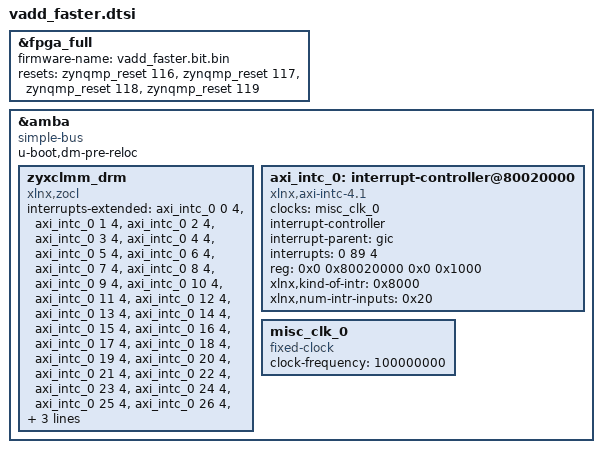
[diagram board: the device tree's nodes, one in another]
/dts-v1/;
/plugin/;

&fpga_full {
	#address-cells = <2>;
	#size-cells = <2>;
	firmware-name = "vadd_faster.bit.bin";
	resets = <&zynqmp_reset 116>, <&zynqmp_reset 117>, <&zynqmp_reset 118>, <&zynqmp_reset 119>;
};

&amba {
	compatible = "simple-bus";
	u-boot,dm-pre-reloc;
	#address-cells = <0x02>;
	#size-cells = <0x02>;

	zyxclmm_drm {
		// compatible = "xlnx,zocl";
		// status = "okay";
		compatible = "xlnx,zocl";
		interrupts-extended = <&axi_intc_0 0 4>, <&axi_intc_0 1 4>, <&axi_intc_0 2 4>, <&axi_intc_0 3 4>, <&axi_intc_0 4 4>, <&axi_intc_0 5 4>, 
			<&axi_intc_0 6 4>, <&axi_intc_0 7 4>, <&axi_intc_0 8 4>, <&axi_intc_0 9 4>,
			<&axi_intc_0 10 4>, <&axi_intc_0 11 4>, <&axi_intc_0 12 4>, <&axi_intc_0 13 4>, <&axi_intc_0 14 4>,
			<&axi_intc_0 15 4>, <&axi_intc_0 16 4>, <&axi_intc_0 17 4>, <&axi_intc_0 18 4>, <&axi_intc_0 19 4>,
			<&axi_intc_0 20 4>, <&axi_intc_0 21 4>, <&axi_intc_0 22 4>, <&axi_intc_0 23 4>, <&axi_intc_0 24 4>,
			<&axi_intc_0 25 4>, <&axi_intc_0 26 4>, <&axi_intc_0 27 4>, <&axi_intc_0 28 4>, <&axi_intc_0 29 4>,
			<&axi_intc_0 30 4>, <&axi_intc_0 31 4 >;
	};

	axi_intc_0: interrupt-controller@80020000 {
		#interrupt-cells = <2>;
		clock-names = "s_axi_aclk";
		clocks = <&misc_clk_0>;
		compatible = "xlnx,axi-intc-4.1", "xlnx,xps-intc-1.00.a";
		interrupt-controller ;
		interrupt-names = "irq";
		interrupt-parent = <&gic>;
		// interrupt-parent = <"/axi/interrupt-controller@f9010000">;
		interrupts = <0 89 4>;
		reg = <0x0 0x80020000 0x0 0x1000>;
		xlnx,kind-of-intr = <0x8000>;
		xlnx,num-intr-inputs = <0x20>;
	};

	misc_clk_0: misc_clk_0 {
		#clock-cells = <0>;
		clock-frequency = <100000000>;
		compatible = "fixed-clock";
	};
};


// / {
// 	compatible = "xlnx,zynqmp-sk-kv260-revB\0xlnx,zynqmp-sk-kv260-revA\0xlnx,zynqmp-sk-kv260-revY\0xlnx,zynqmp-sk-kv260-revZ\0xlnx,zynqmp-sk-kv260\0xlnx,zynqmp";

// 	amba_pl: amba_pl@0 {
// 		#address-cells = <2>;
// 		#size-cells = <2>;
// 		compatible = "simple-bus";
// 		ranges ;
// 		axi_intc_0: interrupt-controller@80020000 {
// 			#interrupt-cells = <2>;
// 			clock-names = "s_axi_aclk";
// 			clocks = <&misc_clk_0>;
// 			compatible = "xlnx,axi-intc-4.1", "xlnx,xps-intc-1.00.a";
// 			interrupt-controller ;
// 			interrupt-names = "irq";
// 			interrupt-parent = <&gic>;
// 			// interrupt-parent = <"/axi/interrupt-controller@f9010000">;
// 			interrupts = <0 89 4>;
// 			reg = <0x0 0x80020000 0x0 0x1000>;
// 			xlnx,kind-of-intr = <0x8000>;
// 			xlnx,num-intr-inputs = <0x20>;
// 		};
// 		misc_clk_0: misc_clk_0 {
// 			#clock-cells = <0>;
// 			clock-frequency = <100000000>;
// 			compatible = "fixed-clock";
// 		};
// 		axi_mcdma_0: axi_mcdma@80000000 {
// 			#dma-cells = <1>;
// 			clock-names = "s_axi_aclk", "s_axi_lite_aclk";
// 			clocks = <&misc_clk_1>, <&misc_clk_0>;
// 			compatible = "xlnx,axi-mcdma-1.1", "xlnx,axi-mcdma-1.00.a";
// 			interrupt-names = "mm2s_ch1_introut", "mm2s_ch2_introut", "s2mm_ch1_introut", "s2mm_ch2_introut", "s2mm_ch3_introut", "s2mm_ch4_introut";
// 			interrupt-parent = <&axi_intc_0>;
// 			interrupts = <9 2 10 2 11 2 12 2 13 2 14 2>;
// 			reg = <0x0 0x80000000 0x0 0x1000>;
// 			xlnx,addrwidth = <0x20>;
// 			xlnx,dlytmr-resolution = <0x7d>;
// 			xlnx,enable-single-intr = <0x0>;
// 			xlnx,group1-mm2s = <0xb>;
// 			xlnx,group1-s2mm = <0x457>;
// 			xlnx,group2-mm2s = <0x0>;
// 			xlnx,group2-s2mm = <0x0>;
// 			xlnx,group3-mm2s = <0x0>;
// 			xlnx,group3-s2mm = <0x0>;
// 			xlnx,group4-mm2s = <0x0>;
// 			xlnx,group4-s2mm = <0x0>;
// 			xlnx,group5-mm2s = <0x0>;
// 			xlnx,group5-s2mm = <0x0>;
// 			xlnx,group6-mm2s = <0x0>;
// 			xlnx,group6-s2mm = <0x0>;
// 			xlnx,include-dre ;
// 			xlnx,include-mm2s = <0x1>;
// 			xlnx,include-mm2s-dre = <0x1>;
// 			xlnx,include-mm2s-sf = <0x1>;
// 			xlnx,include-s2mm = <0x1>;
// 			xlnx,include-s2mm-dre = <0x1>;
// 			xlnx,include-s2mm-sf = <0x1>;
// 			xlnx,include-sg ;
// 			xlnx,mm2s-burst-size = <0x10>;
// 			xlnx,mm2s-scheduler = <0x0>;
// 			xlnx,num-mm2s-channels = <0x2>;
// 			xlnx,num-s2mm-channels = <0x4>;
// 			xlnx,prmry-is-aclk-async = <0x0>;
// 			xlnx,s2mm-burst-size = <0x10>;
// 			xlnx,sg-include-stscntrl-strm = <0x0>;
// 			xlnx,sg-length-width = <0xe>;
// 			xlnx,sg-use-stsapp-length = <0x0>;
// 			dma-channel@80000000 {
// 				compatible = "xlnx,axi-dma-mm2s-channel";
// 				dma-channels = <0x2>;
// 				interrupt-parent = <&axi_intc_0>;
// 				interrupts = <9 2 10 2>;
// 				xlnx,datawidth = <0x20>;
// 				xlnx,device-id = <0x0>;
// 				xlnx,include-dre ;
// 			};
// 			dma-channel@80000030 {
// 				compatible = "xlnx,axi-dma-s2mm-channel";
// 				dma-channels = <0x4>;
// 				interrupt-parent = <&axi_intc_0>;
// 				interrupts = <11 2 12 2 13 2 14 2>;
// 				xlnx,datawidth = <0x20>;
// 				xlnx,device-id = <0x0>;
// 				xlnx,include-dre ;
// 			};
// 		};
// 		misc_clk_1: misc_clk_1 {
// 			#clock-cells = <0>;
// 			clock-frequency = <200000000>;
// 			compatible = "fixed-clock";
// 		};
// 		axi_uartlite_0: serial@80010000 {
// 			clock-names = "s_axi_aclk";
// 			clocks = <&misc_clk_0>;
// 			compatible = "xlnx,axi-uartlite-2.0", "xlnx,xps-uartlite-1.00.a";
// 			current-speed = <9600>;
// 			device_type = "serial";
// 			interrupt-names = "interrupt";
// 			interrupt-parent = <&axi_intc_0>;
// 			interrupts = <15 0>;
// 			port-number = <1>;
// 			reg = <0x0 0x80010000 0x0 0x10000>;
// 			xlnx,baudrate = <0x2580>;
// 			xlnx,data-bits = <0x8>;
// 			xlnx,odd-parity = <0x0>;
// 			xlnx,s-axi-aclk-freq-hz-d = "100.0";
// 			xlnx,txen-delay = <0x0>;
// 			xlnx,use-parity = <0x0>;
// 		};
// 		// tsn_endpoint_ip_0: tsn_endpoint_ip_0 {
// 		// 	#address-cells = <2>;
// 		// 	#size-cells = <2>;
// 		// 	clock-names = "host_txfifo_aclk", "host_rxfifo_aclk", "s_axi_aclk", "gtx_clk", "gtx_clk90", "refclk";
// 		// 	clocks = <&misc_clk_1>, <&misc_clk_1>, <&misc_clk_0>, <&misc_clk_2>, <&misc_clk_2>, <&misc_clk_3>;
// 		// 	compatible = "xlnx,tsn-endpoint-ethernet-mac-2.0";
// 		// 	interrupt-names = "interrupt_ptp_rx_1", "interrupt_ptp_tx_1", "mac_irq_1", "tsn_ep_scheduler_irq", "interrupt_ptp_timer", "interrupt_ptp_rx_2", "interrupt_ptp_tx_2", "mac_irq_2";
// 		// 	interrupt-parent = <&axi_intc_0>;
// 		// 	interrupts = <0 2 2 2 4 2 7 2 6 2 1 2 3 2 5 2>;
// 		// 	ranges ;
// 		// 	reg = <0x0 0x80040000 0x0 0x40000>;
// 		// 	tsn_emac_0: tsn_emac_0@80040000 {
// 		// 		axistream-connected-rx = <&axi_mcdma_0>, <&axi_mcdma_0>;
// 		// 		axistream-connected-tx = <&axi_mcdma_0>, <&ta_dma_0>;
// 		// 		clock-frequency = <100000000>;
// 		// 		compatible = "xlnx,tsn-ethernet-1.00.a";
// 		// 		interrupt-names = "interrupt_ptp_rx_1", "interrupt_ptp_tx_1", "mac_irq_1", "interrupt_ptp_timer";
// 		// 		interrupt-parent = <&axi_intc_0>;
// 		// 		interrupts = <0 2 2 2 4 2 6 2>;
// 		// 		local-mac-address = [00 0A 35 00 01 0e];
// 		// 		phy-handle = <&phy1>;
// 		// 		phy-mode = "rgmii";
// 		// 		reg = <0x0 0x80040000 0x0 0x14000>;
// 		// 		tsn,endpoint = <&tsn_ep>;
// 		// 		xlnx,channel-ids = "1","2","3","4";
// 		// 		xlnx,eth-hasnobuf ;
// 		// 		xlnx,num-queues = /bits/ 16 <0x4>;
// 		// 		xlnx,num-tc = /bits/ 16 <0x2>;
// 		// 		xlnx,phy-type = <0x3>;
// 		// 		xlnx,qbv-addr = <0x80054000>;
// 		// 		xlnx,qbv-size = <0x2000>;
// 		// 		xlnx,rxsum = <0>;
// 		// 		xlnx,tsn ;
// 		// 		xlnx,txsum = <0>;
// 		// 		my_tsn_ip_mdio0: mdio {
// 		// 			#address-cells = <1>;
// 		// 			#size-cells = <0>;
// 		// 			phy1: phy@1 {
// 		// 				compatible = "marvell,88e1111";
// 		// 				device_type = "ethernet-phy";
// 		// 				reg = <0>;
// 		// 			};
// 		// 		};
// 		// 	};
// 		// 	epswitch: tsn_switch@80078000 {
// 		// 		compatible = "xlnx,tsn-switch";
// 		// 		ports = <&tsn_ep>, <&tsn_emac_0>, <&tsn_emac_1>;
// 		// 		reg = <0x0 0x80078000 0x0 0x00008000>;
// 		// 		xlnx,has-hwaddr-learning ;
// 		// 		xlnx,num-ports = /bits/ 16 <0x3>;
// 		// 		xlnx,num-tc = /bits/ 16 <0x2>;
// 		// 	};
// 		// 	tsn_ep: tsn_ep@80056000 {
// 		// 		axistream-connected-rx = <&axi_mcdma_0>, <&axi_mcdma_0>;
// 		// 		axistream-connected-tx = <&axi_mcdma_0>, <&ta_dma_0>;
// 		// 		compatible = "xlnx,tsn-ep";
// 		// 		interrupt-names = "tsn_ep_scheduler_irq", "mm2s_ch1_introut", "mm2s_ch2_introut", "s2mm_ch1_introut", "s2mm_ch2_introut", "s2mm_ch3_introut", "s2mm_ch4_introut";
// 		// 		interrupt-parent = <&axi_intc_0>;
// 		// 		interrupts = <7 2 9 2 10 2 11 2 12 2 13 2 14 2>;
// 		// 		local-mac-address = [00 0A 35 00 01 05];
// 		// 		reg = <0x0 0x80056000 0x0 0xA000>;
// 		// 		xlnx,channel-ids = "1","2","3","4";
// 		// 		xlnx,eth-hasnobuf ;
// 		// 		xlnx,num-tc = /bits/ 16 <0x2>;
// 		// 	};
// 		// 	tsn_emac_1: tsn_emac_1@80060000 {
// 		// 		clock-frequency = <100000000>;
// 		// 		compatible = "xlnx,tsn-ethernet-1.00.a";
// 		// 		interrupt-names = "interrupt_ptp_rx_2", "interrupt_ptp_tx_2", "mac_irq_2";
// 		// 		interrupt-parent = <&axi_intc_0>;
// 		// 		interrupts = <1 2 3 2 5 2>;
// 		// 		local-mac-address = [00 0A 35 00 01 0f];
// 		// 		phy-handle = <&phy2>;
// 		// 		phy-mode = "rgmii";
// 		// 		reg = <0x0 0x80060000 0x0 0x14000>;
// 		// 		tsn,endpoint = <&tsn_ep>;
// 		// 		xlnx,eth-hasnobuf ;
// 		// 		xlnx,num-queues = /bits/ 16 <0x4>;
// 		// 		xlnx,num-tc = /bits/ 16 <0x2>;
// 		// 		xlnx,phy-type = <0x3>;
// 		// 		xlnx,qbv-addr = <0x80074000>;
// 		// 		xlnx,qbv-size = <0x4000>;
// 		// 		xlnx,rxsum = <0>;
// 		// 		xlnx,tsn ;
// 		// 		xlnx,tsn-slave ;
// 		// 		xlnx,txsum = <0>;
// 		// 		my_tsn_ip_mdio1: mdio {
// 		// 			#address-cells = <1>;
// 		// 			#size-cells = <0>;
// 		// 			phy2: phy@2 {
// 		// 				compatible = "marvell,88e1111";
// 		// 				device_type = "ethernet-phy";
// 		// 				reg = <0>;
// 		// 			};
// 		// 		};
// 		// 	};
// 		// };
// 		misc_clk_2: misc_clk_2 {
// 			#clock-cells = <0>;
// 			clock-frequency = <125000000>;
// 			compatible = "fixed-clock";
// 		};
// 		misc_clk_3: misc_clk_3 {
// 			#clock-cells = <0>;
// 			clock-frequency = <300000000>;
// 			compatible = "fixed-clock";
// 		};
// 		ta_dma_0: ta_dma@90000000 {
// 			clock-names = "dma_clk", "rtc_clk";
// 			clocks = <&misc_clk_1>, <&misc_clk_2>;
// 			compatible = "xlnx,ta-dma-1.0";
// 			interrupt-names = "introut";
// 			interrupt-parent = <&axi_intc_0>;
// 			interrupts = <8 2>;
// 			reg = <0x0 0x90000000 0x0 0x800000>;
// 			xlnx,en-debug = <0x0>;
// 			xlnx,en-int-store-and-fwd = <0x1>;
// 			xlnx,en-statistics = <0x1>;
// 			xlnx,en-unaligined-addr-support = "true";
// 			xlnx,num-buffers-per-stream = <0x40>;
// 			xlnx,num-fetch-entries = <0x8>;
// 			xlnx,num-streams = <0x8>;
// 		};
// 		zyxclmm_drm {
// 			compatible = "xlnx,zocl";
// 			status = "okay";
			
// 			// compatible = "xlnx,zocl";
// 			// interrupts-extended = <&axi_intc_0 0 4>, <&axi_intc_0 1 4>, <&axi_intc_0 2 4>, <&axi_intc_0 3 4>, <&axi_intc_0 4 4>, <&axi_intc_0 5 4>, 
// 			// 	<&axi_intc_0 6 4>, <&axi_intc_0 7 4>, <&axi_intc_0 8 4>, <&axi_intc_0 9 4>,
// 			// 	<&axi_intc_0 10 4>, <&axi_intc_0 11 4>, <&axi_intc_0 12 4>, <&axi_intc_0 13 4>, <&axi_intc_0 14 4>,
// 			// 	<&axi_intc_0 15 4>, <&axi_intc_0 16 4>, <&axi_intc_0 17 4>, <&axi_intc_0 18 4>, <&axi_intc_0 19 4>,
// 			// 	<&axi_intc_0 20 4>, <&axi_intc_0 21 4>, <&axi_intc_0 22 4>, <&axi_intc_0 23 4>, <&axi_intc_0 24 4>,
// 			// 	<&axi_intc_0 25 4>, <&axi_intc_0 26 4>, <&axi_intc_0 27 4>, <&axi_intc_0 28 4>, <&axi_intc_0 29 4>,
// 			// 	<&axi_intc_0 30 4>, <&axi_intc_0 31 4 >;
// 		};
// 	};
// };

// / {
// 	compatible = "xlnx,zynqmp-sk-kv260-revB\0xlnx,zynqmp-sk-kv260-revA\0xlnx,zynqmp-sk-kv260-revY\0xlnx,zynqmp-sk-kv260-revZ\0xlnx,zynqmp-sk-kv260\0xlnx,zynqmp";

// 	fragment@0 {
// 		target = <0xffffffff>;

// 		__overlay__ {
// 			#address-cells = <0x02>;
// 			#size-cells = <0x02>;
// 			firmware-name = "kv260-dp.bit.bin";
// 			fpga-config-from-dmabuf;
// 			phandle = <0x01>;
// 		};
// 	};

// 	fragment4 {
// 		target = <0xffffffff>;

// 		__overlay__ {
// 			status = "okay";
// 		};
// 	};

// 	fragment5 {
// 		target = <0xffffffff>;

// 		__overlay__ {
// 			status = "okay";
// 		};
// 	};

// 	fragment6 {
// 		target = <0xffffffff>;

// 		__overlay__ {
// 			status = "okay";
// 		};
// 	};

// 	fragment7 {
// 		target = <0xffffffff>;

// 		__overlay__ {
// 			status = "okay";
// 		};
// 	};

// 	fragment8 {
// 		target = <0xffffffff>;

// 		__overlay__ {
// 			status = "okay";
// 		};
// 	};

// 	__symbols__ {
// 		overlay0 = "/fragment@0/__overlay__";
// 	};

// 	__fixups__ {
// 		fpga_full = "/fragment@0:target:0";
// 		zynqmp_dpsub = "/fragment4:target:0";
// 		zynqmp_dp_snd_pcm0 = "/fragment5:target:0";
// 		zynqmp_dp_snd_pcm1 = "/fragment6:target:0";
// 		zynqmp_dp_snd_card0 = "/fragment7:target:0";
// 		zynqmp_dp_snd_codec0 = "/fragment8:target:0";
// 	};
// };
